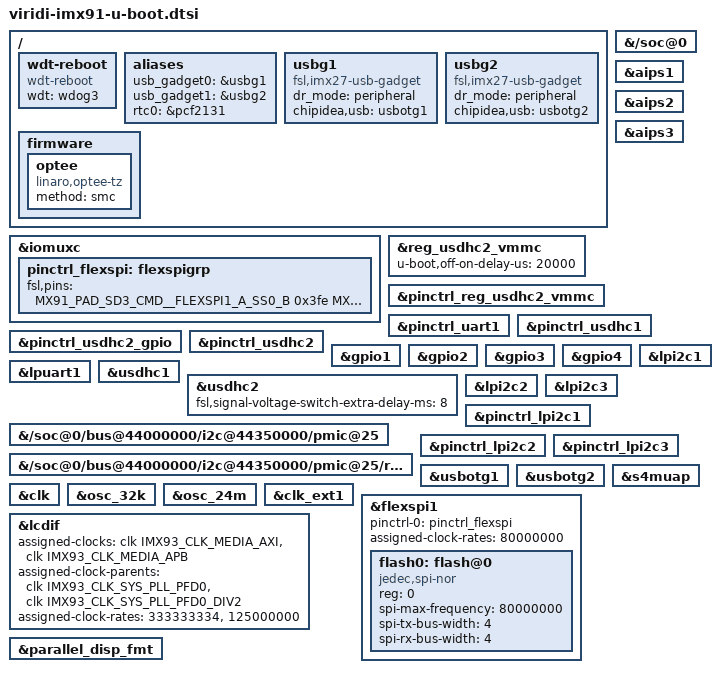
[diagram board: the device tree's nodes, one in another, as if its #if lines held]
// SPDX-License-Identifier: GPL-2.0+
/*
 * Copyright 2024 NXP
 */

#include "imx91-u-boot.dtsi"

/ {
	wdt-reboot {
		compatible = "wdt-reboot";
		wdt = <&wdog3>;
		bootph-pre-ram;
		bootph-some-ram;
	};

	aliases {
		usb_gadget0 = &usbg1;
		usb_gadget1 = &usbg2;
		rtc0 = &pcf2131;
	};

	usbg1: usbg1 {
		compatible = "fsl,imx27-usb-gadget";
		dr_mode = "peripheral";
		chipidea,usb = <&usbotg1>;
		status = "okay";
	};

	usbg2: usbg2 {
		compatible = "fsl,imx27-usb-gadget";
		dr_mode = "peripheral";
		chipidea,usb = <&usbotg2>;
		status = "okay";
	};

	firmware {
		optee {
			compatible = "linaro,optee-tz";
			method = "smc";
		};
	};
};

&{/soc@0} {
	bootph-all;
	bootph-pre-ram;
};

&aips1 {
	bootph-pre-ram;
	bootph-all;
};

&aips2 {
	bootph-pre-ram;
	bootph-some-ram;
};

&aips3 {
	bootph-pre-ram;
	bootph-some-ram;
};

&iomuxc {
	bootph-pre-ram;
	bootph-some-ram;

	pinctrl_flexspi: flexspigrp {
		fsl,pins = <
			MX91_PAD_SD3_CMD__FLEXSPI1_A_SS0_B      0x3fe
			MX91_PAD_SD3_CLK__FLEXSPI1_A_SCLK       0x3fe
			MX91_PAD_SD3_DATA0__FLEXSPI1_A_DATA0   0x3fe
			MX91_PAD_SD3_DATA1__FLEXSPI1_A_DATA1   0x3fe
			MX91_PAD_SD3_DATA2__FLEXSPI1_A_DATA2   0x3fe
			MX91_PAD_SD3_DATA3__FLEXSPI1_A_DATA3   0x3fe
		>;
	};
};

&reg_usdhc2_vmmc {
	u-boot,off-on-delay-us = <20000>;
	bootph-pre-ram;
	bootph-some-ram;
};

&pinctrl_reg_usdhc2_vmmc {
	bootph-pre-ram;
};

&pinctrl_uart1 {
	bootph-pre-ram;
	bootph-some-ram;
};

&pinctrl_usdhc1 {
	bootph-pre-ram;
	bootph-some-ram;
};

&pinctrl_usdhc2_gpio {
	bootph-pre-ram;
	bootph-some-ram;
};

&pinctrl_usdhc2 {
	bootph-pre-ram;
	bootph-some-ram;
};

&gpio1 {
	bootph-pre-ram;
	bootph-some-ram;
};

&gpio2 {
	bootph-pre-ram;
	bootph-some-ram;
};

&gpio3 {
	bootph-pre-ram;
	bootph-some-ram;
};

&gpio4 {
	bootph-pre-ram;
	bootph-some-ram;
};

&lpuart1 {
	bootph-pre-ram;
	bootph-some-ram;
};

&usdhc1 {
	bootph-pre-ram;
	bootph-some-ram;
};

&usdhc2 {
	bootph-pre-ram;
	bootph-some-ram;
	fsl,signal-voltage-switch-extra-delay-ms = <8>;
};

&lpi2c1 {
	bootph-pre-ram;
	bootph-some-ram;
};

&lpi2c2 {
	bootph-pre-ram;
	bootph-some-ram;
};

&lpi2c3 {
	bootph-pre-ram;
	bootph-some-ram;

};

&{/soc@0/bus@44000000/i2c@44350000/pmic@25} {
	bootph-pre-ram;
	bootph-some-ram;
};

&{/soc@0/bus@44000000/i2c@44350000/pmic@25/regulators} {
	bootph-pre-ram;
	bootph-some-ram;
};

&pinctrl_lpi2c1 {
	bootph-pre-ram;
	bootph-some-ram;
};

&pinctrl_lpi2c2 {
	bootph-pre-ram;
	bootph-some-ram;
};

&pinctrl_lpi2c3 {
	bootph-pre-ram;
	bootph-some-ram;
};


&usbotg1 {
	status = "okay";
};

&usbotg2 {
	status = "okay";
};

&s4muap {
	bootph-pre-ram;
	bootph-some-ram;
	status = "okay";
};

&clk {
	bootph-all;
	bootph-pre-ram;
	/delete-property/ assigned-clocks;
	/delete-property/ assigned-clock-rates;
	/delete-property/ assigned-clock-parents;
};

&osc_32k {
	bootph-all;
	bootph-pre-ram;
};

&osc_24m {
	bootph-all;
	bootph-pre-ram;
};

&clk_ext1 {
	bootph-all;
	bootph-pre-ram;
};

&flexspi1 {
	pinctrl-names = "default";
	pinctrl-0 = <&pinctrl_flexspi>;
	assigned-clock-rates = <80000000>;
	status = "okay";

	flash0: flash@0 {
		reg = <0>;
		#address-cells = <1>;
		#size-cells = <1>;
		compatible = "jedec,spi-nor";
		spi-max-frequency = <80000000>;
		spi-tx-bus-width = <4>;
		spi-rx-bus-width = <4>;
	};
};

&lcdif {
	assigned-clocks = <&clk IMX93_CLK_MEDIA_AXI>, <&clk IMX93_CLK_MEDIA_APB>;
	assigned-clock-parents = <&clk IMX93_CLK_SYS_PLL_PFD0>, <&clk IMX93_CLK_SYS_PLL_PFD0_DIV2>;
	assigned-clock-rates = <333333334>, <125000000>;
};

&parallel_disp_fmt {
	/delete-property/ power-domains;
};

#ifdef CONFIG_MTD_SPI_NAND
#include "imx91-11x11-evk-spinand.dtsi"
#endif
